# TPCC register map
Vendor: Texas Instruments
Peripheral module from a debugger description file (folder omap36xx).
Registers are 32-bit, read-write, reset values left out (the file's numbers can be read two ways) unless marked. A register's access mark holds for its fields unless they carry their own. Offsets are as the file gives them; lines under a group give offsets from that group; [hi:lo] are bit positions; {n}, {i} and the like mark numbered series; 'fields as' and 'values as' point back to an identical list; <NAME> marks a mode.

## TPCC (part 1 of 2)
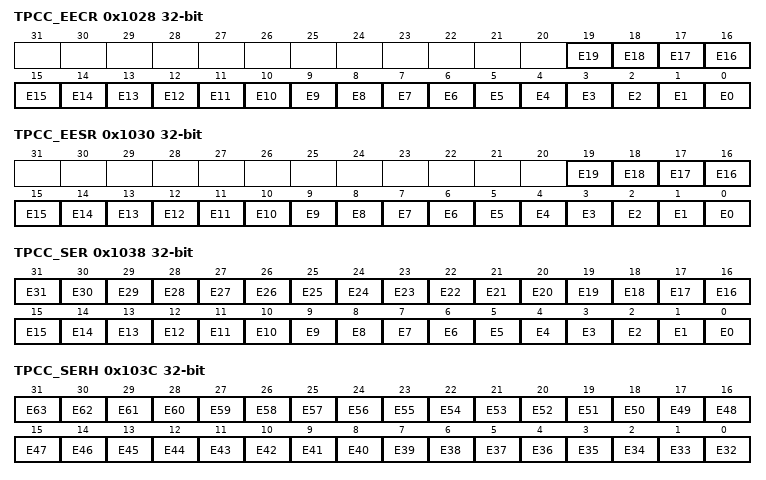
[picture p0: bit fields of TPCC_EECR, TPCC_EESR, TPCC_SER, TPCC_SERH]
0x1028 TPCC_EECR wo — Event Enable Clear Register: CPU write of 1 to the EECR.En bit causes the EER.En bit to be cleared.CPU write of 0 has no effect.
  [n] E{n} (n=0..19) — Event #{n}
0x1030 TPCC_EESR wo — Event Enable Set Register: CPU write of 1 to the EESR.En bit causes the EER.En bit to be set.CPU write of 0 has no effect.
  [n] E{n} (n=0..19) — Event #{n}
0x1038 TPCC_SER ro — Secondary Event Register: The secondary event register is used along with the Event Register (ER) to provide information on the state of an Event. En = 0: Event is not currently in the Event Queue.En = 1: Event is currently stored in Event Queue. Event arbiter will not prioritize additional events.
  [n] E{n} (n=0..31) — Event #{n}
0x103C TPCC_SERH ro — Secondary Event Register (High Part): The secondary event register is used along with the Event Register (ERH) to provide information on the state of an Event. En = 0: Event is not currently in the Event Queue.En = 1: Event is currently stored in Event Queue. Event arbiter will not prioritize additional events.
  [n-32] E{n} (n=32..63) — Event #{n}
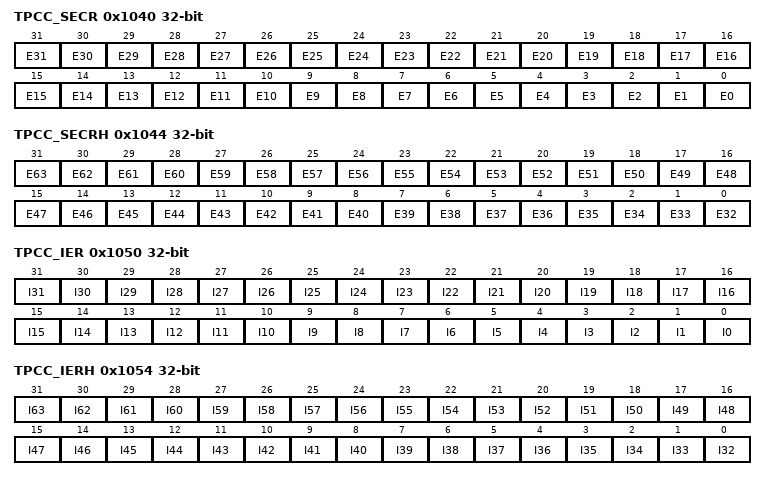
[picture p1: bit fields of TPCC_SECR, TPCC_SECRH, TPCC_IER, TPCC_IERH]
0x1040 TPCC_SECR wo — Secondary Event Clear Register: The secondary event clear register is used to clear the status of the SER registers. CPU write of 1 to the SECR.En bit clears the SER register.CPU write of 0 has no effect.
  [n] E{n} (n=0..31) — Event #{n}
0x1044 TPCC_SECRH wo — Secondary Event Clear Register (High Part): The secondary event clear register is used to clear the status of the SERH registers. CPU write of 1 to the SECRH.En bit clears the SERH register.CPU write of 0 has no effect.
  [n-32] E{n} (n=32..63) — Event #{n}
0x1050 TPCC_IER ro — Int Enable Register: IER.In is not directly writeable. Interrupts can be enabled through writes to IESR and can be disabled through writes to IECR register. IER.In = 0: IPR.In is NOT enabled for interrupts.IER.In = 1: IPR.In IS enabled for interrupts.
  [n] I{n} (n=0..31) — Interrupt associated with TCC #{n}
0x1054 TPCC_IERH ro — Int Enable Register (High Part): IERH.In is not directly writeable. Interrupts canbe enabled through writes to IESRH and can be disabled through writes to IECRH register. IERH.In = 0: IPRH.In is NOT enabled for interrupts.IERH.In = 1: IPRH.In IS enabled for interrupts.
  [n-32] I{n} (n=32..63) — Interrupt associated with TCC #{n}
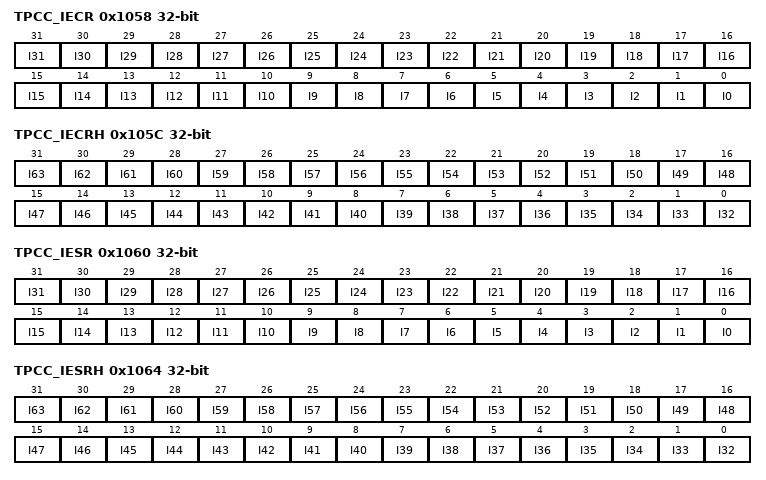
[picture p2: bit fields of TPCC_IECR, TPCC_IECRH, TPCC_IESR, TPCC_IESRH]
0x1058 TPCC_IECR wo — Int Enable Clear Register: CPU write of 1 to the IECR.In bit causes the IER.In bit to be cleared.CPU write of 0 has no effect.
  [n] I{n} (n=0..31) — Interrupt associated with TCC #{n}
0x105C TPCC_IECRH wo — Int Enable Clear Register (High Part): CPU write of 1 to the IECRH.In bit causes the IERH.In bit to be cleared.CPU write of 0 has no effect.
  [n-32] I{n} (n=32..63) — Interrupt associated with TCC #{n}
0x1060 TPCC_IESR wo — Int Enable Set Register: CPU write of 1 to the IESR.In bit causes the IESR.In bit to be set.CPU write of 0 has no effect.
  [n] I{n} (n=0..31) — Interrupt associated with TCC #{n}
0x1064 TPCC_IESRH wo — Int Enable Set Register (High Part): CPU write of 1 to the IESRH.In bit causes the IESRH.In bit to be set.CPU write of 0 has no effect.
  [n-32] I{n} (n=32..63) — Interrupt associated with TCC #{n}
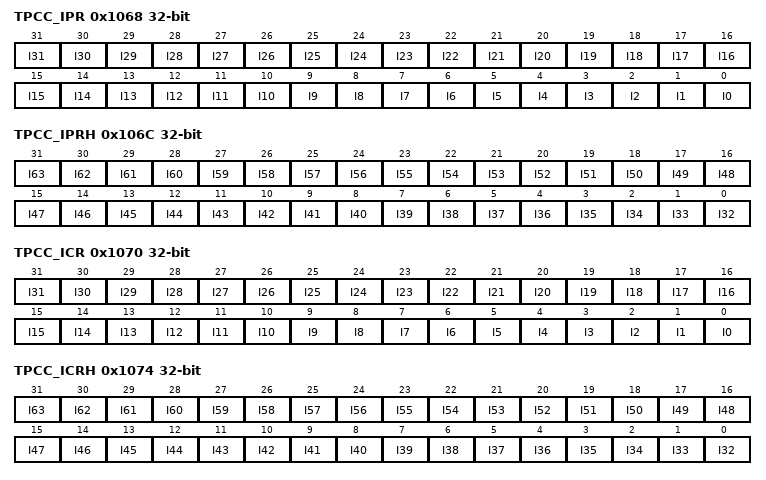
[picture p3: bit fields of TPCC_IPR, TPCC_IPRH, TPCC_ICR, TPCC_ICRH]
0x1068 TPCC_IPR ro — Interrupt Pending Register: IPR.In bit is set when a interrupt completion code with TCC of N is detected.IPR.In bit is cleared through software by writing 1 to ICR.In bit.
  [n] I{n} (n=0..31) — Interrupt associated with TCC #{n}
0x106C TPCC_IPRH ro — Interrupt Pending Register (High Part): IPRH.In bit is set when a interrupt completion code with TCC of N is detected.IPRH.In bit is cleared through software by writing 1 to ICRH.In bit.
  [n-32] I{n} (n=32..63) — Interrupt associated with TCC #{n}
0x1070 TPCC_ICR wo — Interrupt Clear Register: CPU write of 1 to the ICR.In bit causes the IPR.In bit to be cleared.CPU write of 0 has no effect. All IPR.In bits must be cleared before additional interrupts will be asserted by CC.
  [n] I{n} (n=0..31) — Interrupt associated with TCC #{n}
0x1074 TPCC_ICRH wo — Interrupt Clear Register (High Part): CPU write of 1 to the ICRH.In bit causes the IPRH.In bit to be cleared.CPU write of 0 has no effect. All IPRH.In bits must be cleared before additional interrupts will be asserted by CC.
  [n-32] I{n} (n=32..63) — Interrupt associated with TCC #{n}
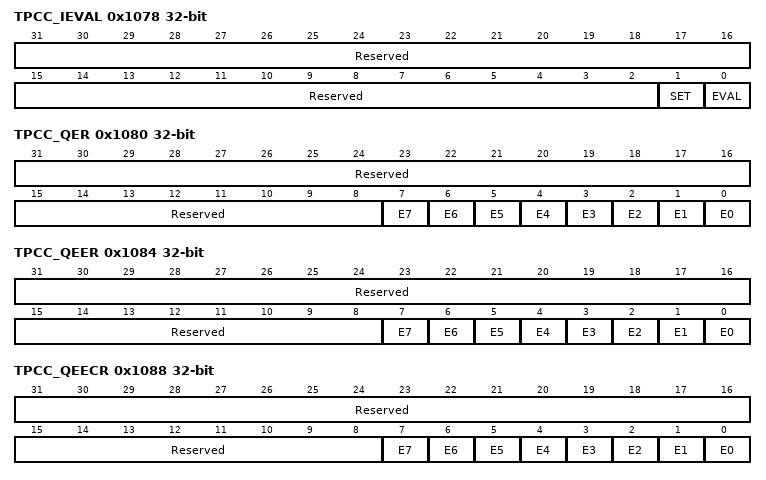
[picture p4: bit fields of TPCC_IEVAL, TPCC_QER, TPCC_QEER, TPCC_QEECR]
0x1078 TPCC_IEVAL wo — Interrupt Eval Register
  [31:2] Reserved — Write 0s for future compatibility.
  [1] SET — Interrupt Set: CPU write of 1 to the SETn bit causes the tpcc_intN output signal to be pulsed egardless of state of interrupts enable (IERn) and status (IPRn).CPU write of 0 has no effect.
  [0] EVAL — Interrupt Evaluate: CPU write of 1 to the EVALn bit causes the tpcc_intN output signal to be pulsed if any enabled interrupts (IERn) are still pending (IPRn).CPU write of 0 has no effect.
0x1080 TPCC_QER ro — QDMA Event Register: If QER.En bit is set, then the corresponding QDMA channel is prioritized vs. other qdma events for submission to the TC. QER.En bit is set when a vbus write byte matches the address defined in the QCHMAPn register. QER.En bit is cleared when the corresponding event is prioritized and serviced. QER.En is also cleared when user writes a 1 to the QSECR.Enbit. If the QER.En bit is already set and a new QDMA event is detected due to user write to QDMA trigger location and QEER register is set, then the corresponding bit in the QDMA Event Missed Register is set.
  [31:8] Reserved — Read returns 0.
  [n] E{n} (n=0..7) — Event #{n}
0x1084 TPCC_QEER ro — QDMA Event Enable Register: Enabled/disabled QDMA address comparator for QDMA Channel N. QEER.En is not directly writeable. QDMA channels can be enabled through writes to QEESR and can be disabled through writes to QEECR register. QEER.En = 1, The corresponding QDMA channel comparator is enabled and Events will be recognized and latched in QER.En.QEER.En = 0, The corresponding QDMA channel comparator is disabled. Events will not be recognized/latched in QER.En.
  [31:8] Reserved — Read returns 0.
  [n] E{n} (n=0..7) — Event #{n}
0x1088 TPCC_QEECR wo — QDMA Event Enable Clear Register: CPU write of 1 to the QEECR.En bit causes the QEER.En bit to be cleared.CPU write of 0 has no effect.
  [31:8] Reserved — Write 0s for future compatibility.
  [n] E{n} (n=0..7) — Event #{n}
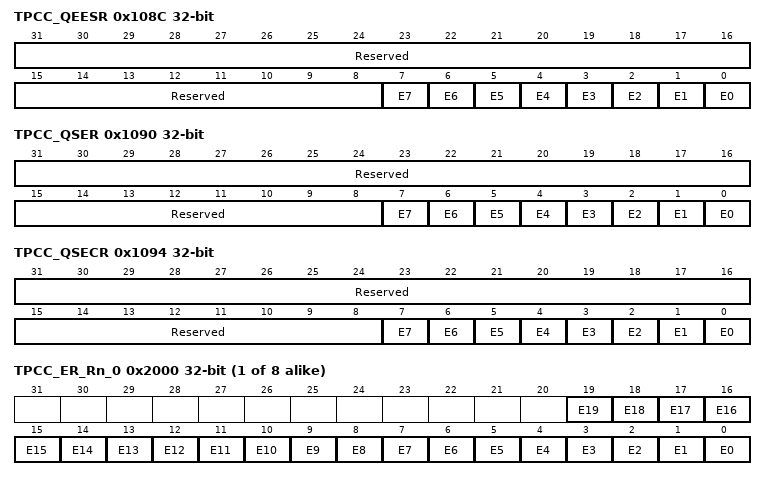
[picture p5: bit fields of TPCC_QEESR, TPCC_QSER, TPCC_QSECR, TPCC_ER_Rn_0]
0x108C TPCC_QEESR wo — QDMA Event Enable Set Register: CPU write of 1 to the QEESR.En bit causes the QEESR.En bit to be set.CPU write of 0 has no effect.
  fields as TPCC_QEECR
0x1090 TPCC_QSER wo — QDMA Secondary Event Register: The QDMA secondary event register is used along with the QDMA Event Register (QER) to provide information on the state of a QDMA Event. En = 0: Event is not currently in the Event Queue.En = 1: Event is currently stored in Event Queue. Event arbiter will not prioritize additional events.
  fields as TPCC_QEECR
0x1094 TPCC_QSECR wo — QDMA Secondary Event Clear Register: The secondary event clear register is used to clear the status of the QSER and QER register (note that this is slightly different than the SER operation, which does not clear the ER.En register). CPU write of 1 to the QSECR.En bit clears the QSER.En and QER.En register fields.CPU write of 0 has no effect.
  fields as TPCC_QEECR
{0x2000+0x200*i} TPCC_ER_Rn_{i} ro (i=0..7) — Event Register: If ER.En bit is set and the EER.En bit is also set, then the corresponding DMA channel is prioritized vs. other pending DMA events for submission to the TC. ER.En bit is set when the input event #n transitions from inactive (low) to active (high), regardless of the state of EER.En bit. ER.En bit is cleared when the corresponding event is prioritized and serviced. If the ER.En bit is already set and a new inactive to active transition is detected on the input event #n input AND the corresponding bit in the EER register is set, then the corresponding bit in the Event Missed Register is set. Event N can be cleared through sw by writing 1 to the ECR pseudo-register.
  [n] E{n} (n=0..19) — Event #{n}
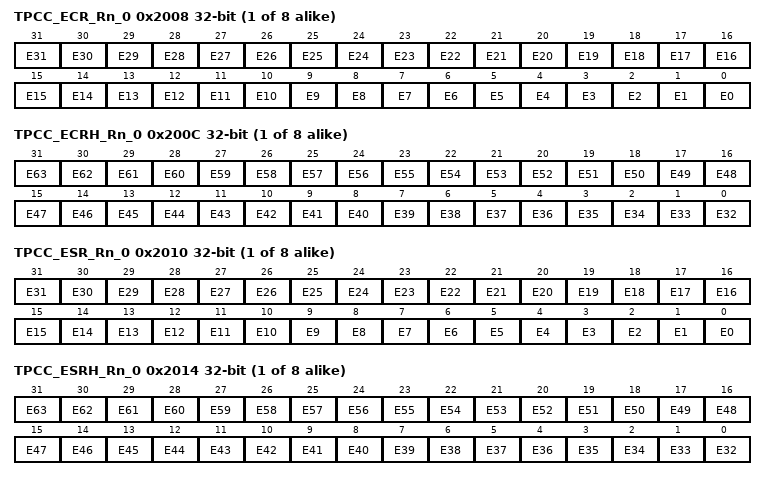
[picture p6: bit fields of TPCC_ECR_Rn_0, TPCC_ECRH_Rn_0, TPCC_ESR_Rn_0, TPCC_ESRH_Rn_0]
{0x2008+0x200*i} TPCC_ECR_Rn_{i} wo (i=0..7) — Event Clear Register: CPU write of 1 to the ECR.En bit causes the ER.En bit to be cleared.CPU write of 0 has no effect.
  [n] E{n} (n=0..31) — Event #{n}
{0x200C+0x200*i} TPCC_ECRH_Rn_{i} wo (i=0..7) — Event Clear Register (High Part): CPU write of 1 to the ECRH.En bit causes the ERH.En bit to be cleared.CPU write of 0 has no effect.
  [n-32] E{n} (n=32..63) — Event #{n}
{0x2010+0x200*i} TPCC_ESR_Rn_{i} wo (i=0..7) — Event Set Register: CPU write of 1 to the ESR.En bit causes the ER.En bit to be set.CPU write of 0 has no effect.
  [n] E{n} (n=0..31) — Event #{n}
{0x2014+0x200*i} TPCC_ESRH_Rn_{i} wo (i=0..7) — Event Set Register (High Part) CPU write of 1 to the ESRH.En bit causes the ERH.En bit to be set.CPU write of 0 has no effect.
  [n-32] E{n} (n=32..63) — Event #{n}
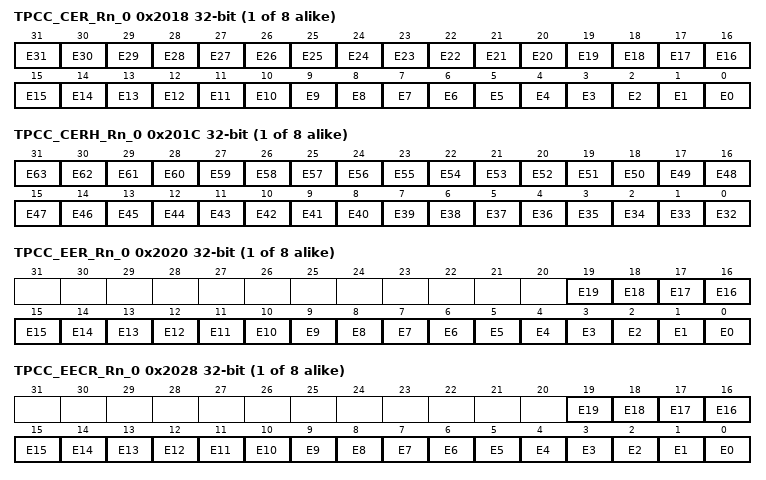
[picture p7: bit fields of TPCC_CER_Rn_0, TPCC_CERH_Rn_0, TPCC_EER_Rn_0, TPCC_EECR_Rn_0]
{0x2018+0x200*i} TPCC_CER_Rn_{i} ro (i=0..7) — Chained Event Register: If CER.En bit is set (regardless of state of EER.En), then the corresponding DMA channel is prioritized vs. other pending DMA events for submission to the TC. CER.En bit is set when a chaining completion code is returned from one of the TPTCs through the completion interface, or is generated internally through Early Completion path. CER.En bit is cleared when the corresponding event is prioritized and serviced. If the CER.En bit is already set and the corresponding chaining completion code is returned from the TC, then the corresponding bit in the Event Missed Register is set. CER.En cannot be set or cleared through software.
  [n] E{n} (n=0..31) — Event #{n}
{0x201C+0x200*i} TPCC_CERH_Rn_{i} ro (i=0..7) — Chained Event Register (High Part): If CERH.En bit is set (regardless of state of EERH.En), then the corresponding DMA channel is prioritized vs. other pending DMA events for submission to the TC. CERH.En bit is set when a chaining completion code is returned from one of the TPTCs through the completion interface, or is generated internally through Early Completion path. CERH.En bit is cleared when the corresponding event is prioritized and serviced. If the CERH.En bit is already set and the corresponding chaining completion code is returned from the TC, then the corresponding bit in the Event Missed Register is set. CERH.En cannot be set or cleared through software.
  [n-32] E{n} (n=32..63) — Event #{n}
{0x2020+0x200*i} TPCC_EER_Rn_{i} ro (i=0..7) — Event Enable Register: Enables DMA transfers for ER.En pending events. ER.En is set based on externally asserted events (through tpcc_eventN_pi). This register has no effect on Chained Event Register (CER) or Event Set Register (ESR). Note that if a bit is set in ER.En while EER.En is disabled, no action is taken. If EER.En is enabled at a later point (and ER.En has not been cleared through SW) then the event will be recognized as a valid TR Sync EER.En is not directly writeable. Events can be enabled through writes to EESR and can be disabled through writes to EECR register. EER.En = 0: ER.En is not enabled to trigger DMA transfers.EER.En = 1: ER.En is enabled to trigger DMA transfers.
  [n] E{n} (n=0..19) — Event #{n}
{0x2028+0x200*i} TPCC_EECR_Rn_{i} wo (i=0..7) — Event Enable Clear Register: CPU write of 1 to the EECR.En bit causes the EER.En bit to be cleared.CPU write of 0 has no effect.
  [n] E{n} (n=0..19) — Event #{n}
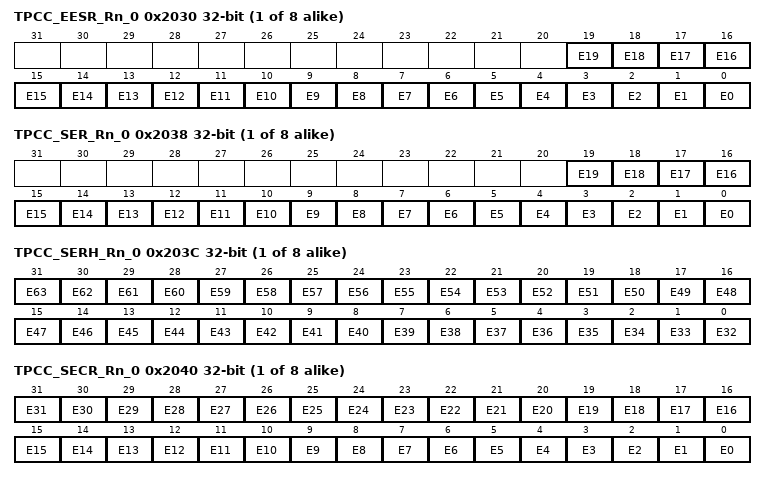
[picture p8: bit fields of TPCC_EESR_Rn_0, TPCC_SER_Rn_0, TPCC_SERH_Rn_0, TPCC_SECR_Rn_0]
{0x2030+0x200*i} TPCC_EESR_Rn_{i} wo (i=0..7) — Event Enable Set Register: CPU write of 1 to the EESR.En bit causes the EER.En bit to be set.CPU write of 0 has no effect.
  [n] E{n} (n=0..19) — Event #{n}
{0x2038+0x200*i} TPCC_SER_Rn_{i} ro (i=0..7) — Secondary Event Register: The secondary event register is used along with the Event Register (ER) to provide information on the state of an Event. En = 0: Event is not currently in the Event Queue.En = 1: Event is currently stored in Event Queue. Event arbiter will not prioritize additional events.
  [n] E{n} (n=0..19) — Event #{n}
{0x203C+0x200*i} TPCC_SERH_Rn_{i} ro (i=0..7) — Secondary Event Register (High Part): The secondary event register is used along with the Event Register (ERH) to provide information on the state of an Event. En = 0: Event is not currently in the Event Queue.En = 1: Event is currently stored in Event Queue. Event arbiter will not prioritize additional events.
  [n-32] E{n} (n=32..63) — Event #{n}
{0x2040+0x200*i} TPCC_SECR_Rn_{i} wo (i=0..7) — Secondary Event Clear Register: The secondary event clear register is used to clear the status of the SER registers. CPU write of 1 to the SECR.En bit clears the SER register.CPU write of 0 has no effect.
  [n] E{n} (n=0..31) — Event #{n}
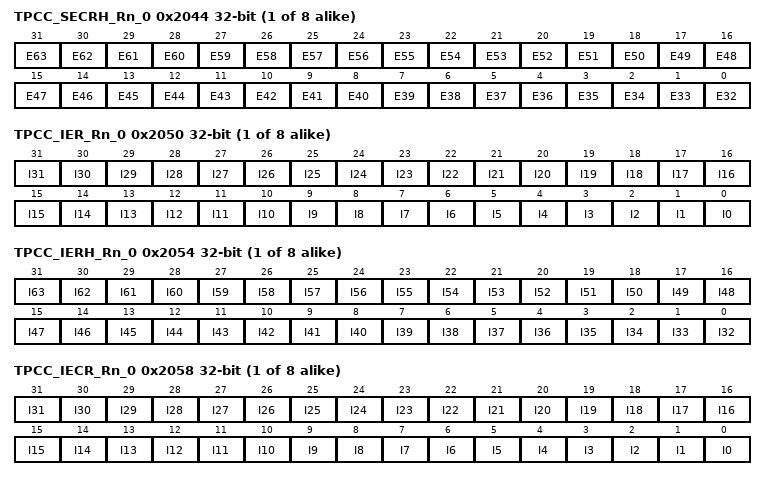
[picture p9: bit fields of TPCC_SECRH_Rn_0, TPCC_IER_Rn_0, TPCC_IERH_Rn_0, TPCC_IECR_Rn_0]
{0x2044+0x200*i} TPCC_SECRH_Rn_{i} wo (i=0..7) — Secondary Event Clear Register (High Part): The secondary event clear register is used to clear the status of the SERH registers. CPU write of 1 to the SECRH.En bit clears the SERH register.CPU write of 0 has no effect.
  [n-32] E{n} (n=32..63) — Event #{n}
{0x2050+0x200*i} TPCC_IER_Rn_{i} ro (i=0..7) — Int Enable Register: IER.In is not directly writeable. Interrupts can be enabled through writes to IESR and can be disabled through writes to IECR register. IER.In = 0: IPR.In is NOT enabled for interrupts.IER.In = 1: IPR.In IS enabled for interrupts.
  [n] I{n} (n=0..31) — Interrupt associated with TCC #{n}
{0x2054+0x200*i} TPCC_IERH_Rn_{i} ro (i=0..7) — Int Enable Register (High Part): IERH.In is not directly writeable. Interrupts can be enabled through writes to IESRH and can be disabled through writes to IECRH register. IERH.In = 0: IPRH.In is NOT enabled for interrupts.IERH.In = 1: IPRH.In IS enabled for interrupts.
  [n-32] I{n} (n=32..63) — Interrupt associated with TCC #{n}
{0x2058+0x200*i} TPCC_IECR_Rn_{i} wo (i=0..7) — Int Enable Clear Register: CPU write of 1 to the IECR.In bit causes the IER.In bit to be cleared.CPU write of 0 has no effect.
  [n] I{n} (n=0..31) — Interrupt associated with TCC #{n}
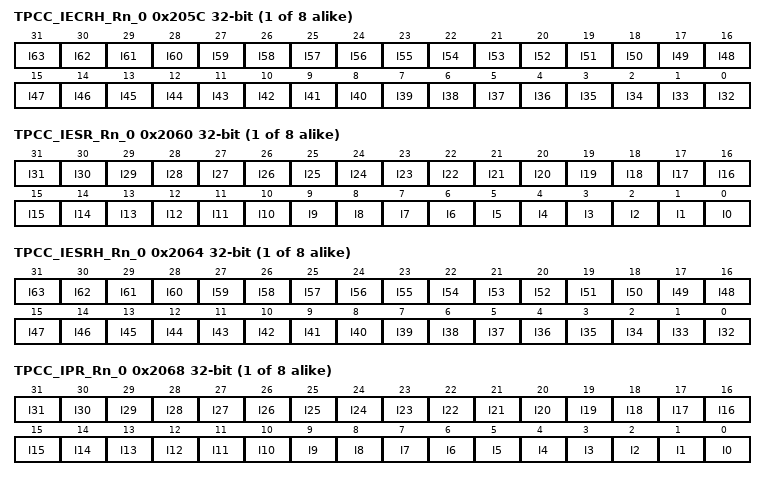
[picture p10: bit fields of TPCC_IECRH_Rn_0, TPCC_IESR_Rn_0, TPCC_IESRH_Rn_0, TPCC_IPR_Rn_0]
{0x205C+0x200*i} TPCC_IECRH_Rn_{i} wo (i=0..7) — Int Enable Clear Register (High Part): CPU write of 1 to the IECRH.In bit causes the IERH.In bit to be cleared.CPU write of 0 has no effect.
  [n-32] I{n} (n=32..63) — Interrupt associated with TCC #{n}
{0x2060+0x200*i} TPCC_IESR_Rn_{i} wo (i=0..7) — Int Enable Set Register: CPU write of 1 to the IESR.In bit causes the IESR.In bit to be set.CPU write of 0 has no effect.
  [n] I{n} (n=0..31) — Interrupt associated with TCC #{n}
{0x2064+0x200*i} TPCC_IESRH_Rn_{i} wo (i=0..7) — Int Enable Set Register (High Part): CPU write of 1 to the IESRH.In bit causes the IESRH.In bit to be set.CPU write of 0 has no effect.
  [n-32] I{n} (n=32..63) — Interrupt associated with TCC #{n}
{0x2068+0x200*i} TPCC_IPR_Rn_{i} ro (i=0..7) — Interrupt Pending Register: IPR.In bit is set when a interrupt completion code with TCC of N is detected.IPR.In bit is cleared through software by writing 1 to ICR.In bit.
  [n] I{n} (n=0..31) — Interrupt associated with TCC #{n}
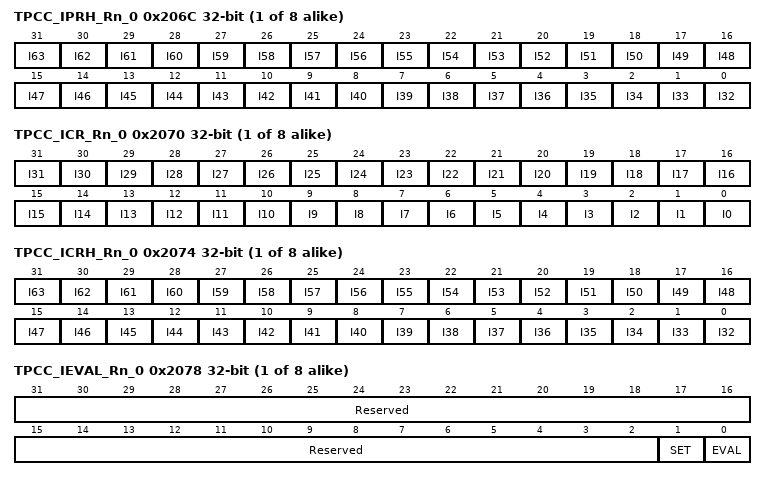
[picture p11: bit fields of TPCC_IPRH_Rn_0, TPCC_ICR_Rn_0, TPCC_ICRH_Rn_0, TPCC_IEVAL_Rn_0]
{0x206C+0x200*i} TPCC_IPRH_Rn_{i} ro (i=0..7) — Interrupt Pending Register (High Part): IPRH.In bit is set when a interrupt completion code with TCC of N is detected.IPRH.In bit is cleared through software by writing 1 to ICRH.In bit.
  [n-32] I{n} (n=32..63) — Interrupt associated with TCC #{n}
{0x2070+0x200*i} TPCC_ICR_Rn_{i} wo (i=0..7) — Interrupt Clear Register: CPU write of 1 to the ICR.In bit causes the IPR.In bit to be cleared.CPU write of 0 has no effect. All IPR.In bits must be cleared before additional interrupts will be asserted by CC.
  [n] I{n} (n=0..31) — Interrupt associated with TCC #{n}
{0x2074+0x200*i} TPCC_ICRH_Rn_{i} wo (i=0..7) — Interrupt Clear Register (High Part): CPU write of 1 to the ICRH.In bit causes the IPRH.In bit to be cleared.CPU write of 0 has no effect. All IPRH.In bits must be cleared before additional interrupts will be asserted by CC.
  [n-32] I{n} (n=32..63) — Interrupt associated with TCC #{n}
{0x2078+0x200*i} TPCC_IEVAL_Rn_{i} wo (i=0..7) — Interrupt Eval Register
  fields as TPCC_IEVAL
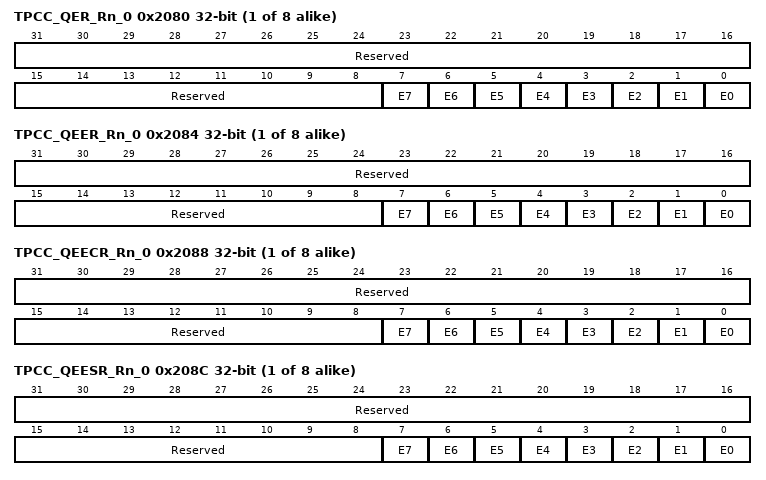
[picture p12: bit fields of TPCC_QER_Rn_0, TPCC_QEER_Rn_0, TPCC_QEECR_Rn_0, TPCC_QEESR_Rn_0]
{0x2080+0x200*i} TPCC_QER_Rn_{i} ro (i=0..7) — QDMA Event Register: If QER.En bit is set, then the corresponding QDMA channel is prioritized vs. other qdma events for submission to the TC. QER.En bit is set when a vbus write byte matches the address defined in the QCHMAPn register. QER.En bit is cleared when the corresponding event is prioritized and serviced. QER.En is also cleared when user writes a 1 to the QSECR.Enbit. If the QER.En bit is already set and a new QDMA event is detected due to user write to QDMA trigger location and QEER register is set, then the corresponding bit in the QDMA Event Missed Register is set.
  [31:8] Reserved — Read returns 0.
  [n] E{n} (n=0..7) — Event #{n}
{0x2084+0x200*i} TPCC_QEER_Rn_{i} ro (i=0..7) — QDMA Event Enable Register: Enabled/disabled QDMA address comparator for QDMA Channel N. QEER.En is not directly writeable. QDMA channels can be enabled through writes to QEESR and can be disabled through writes to QEECR register. QEER.En = 1, The corresponding QDMA channel comparator is enabled and Events will be recognized and latched in QER.En.QEER.En = 0, The corresponding QDMA channel comparator is disabled. Events will not be recognized/latched in QER.En.
  [31:8] Reserved — Read returns 0.
  [n] E{n} (n=0..7) — Event #{n}
{0x2088+0x200*i} TPCC_QEECR_Rn_{i} wo (i=0..7) — QDMA Event Enable Clear Register: CPU write of 1 to the QEECR.En bit causes the QEER.En bit to be cleared.CPU write of 0 has no effect.
  fields as TPCC_QEECR
{0x208C+0x200*i} TPCC_QEESR_Rn_{i} wo (i=0..7) — QDMA Event Enable Set Register: CPU write of 1 to the QEESR.En bit causes the QEESR.En bit to be set.CPU write of 0 has no effect.
  fields as TPCC_QEECR
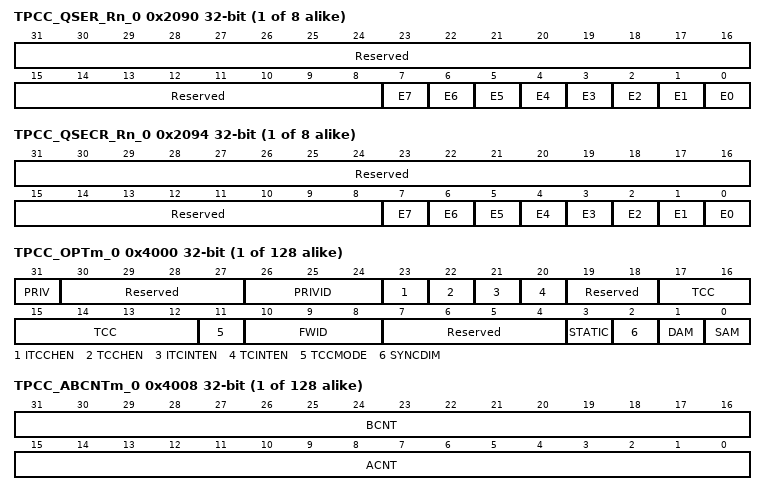
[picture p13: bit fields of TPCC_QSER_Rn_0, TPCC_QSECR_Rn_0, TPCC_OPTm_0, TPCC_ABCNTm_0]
{0x2090+0x200*i} TPCC_QSER_Rn_{i} ro (i=0..7) — QDMA Secondary Event Register: The QDMA secondary event register is used along with the QDMA Event Register (QER) to provide information on the state of a QDMA Event. En = 0: Event is not currently in the Event Queue.En = 1: Event is currently stored in Event Queue. Event arbiter will not prioritize additional events.
  [31:8] Reserved — Read returns 0.
  [n] E{n} (n=0..7) — Event #{n}
{0x2094+0x200*i} TPCC_QSECR_Rn_{i} wo (i=0..7) — QDMA Secondary Event Clear Register: The secondary event clear register is used to clear the status of the QSER and QER register (note that this is slightly different than the SER operation, which does not clear the ER.En register). CPU write of 1 to the QSECR.En bit clears the QSER.En and QER.En register fields.CPU write of 0 has no effect.
  fields as TPCC_QEECR
{0x4000+0x20*i} TPCC_OPTm_{i} access per field (i=0..127) — Options Parameter
  [31] PRIV ro — Privilege level: Privilege level (supervisor vs. user) for the host/cpu/dma that programmed this PaRAM Entry. Value is set with the vbus priv value when any part of the PaRAM Entry is written. Not writeable through vbus wdata bus. Is readable through VBus rdata bus. PRIV = 0: User level privilegePRIV = 1: Supervisor level privilege
  [30:27] Reserved rw — Write 0s for future compatibility.Read returns 0.
  [26:24] PRIVID ro — Privilege ID: Privilege ID for the external host/cpu/dma that programmed this PaRAM Entry. This value is set with the vbus privid value when any part of the PaRAM Entry is written. Not writeable through vbus wdata bus. Is readable through VBus rdata bus.
  [23] ITCCHEN rw — Intermediate transfer completion chaining enable: 0: Intermediate transfer complete chaining is disabled.1: Intermediate transfer complete chaining is enabled.
  [22] TCCHEN rw — Transfer complete chaining enable: 0: Transfer complete chaining is disabled.1: Transfer complete chaining is enabled.
  [21] ITCINTEN rw — Intermediate transfer completion interrupt enable: 0: Intermediate transfer complete interrupt is disabled.1: Intermediate transfer complete interrupt is enabled (corresponding IER[TCC] bit must be set to 1 to generate interrupt)
  [20] TCINTEN rw — Transfer complete interrupt enable: 0: Transfer complete interrupt is disabled.1: Transfer complete interrupt is enabled (corresponding IER[TCC] bit must be set to 1 to generate interrupt)
  [19:18] Reserved rw — Write 0s for future compatibility.Read returns 0.
  [17:12] TCC rw — Transfer Complete Code: The 6-bit code is used to set the relevant bit in CER (bit CER[TCC]) for chaining or in IER (bit IER[TCC]) for interrupts.
  [11] TCCMODE rw — Transfer complete code mode: Indicates the point at which a transfer is considered completed. Applies to both chaining and interrupt. 0: Normal Completion, A transfer is considered completed after the transfer parameters are returned to the CC from the TC (which was returned from the peripheral).1: Early Completion, A transfer is considered completed after the CC submits a TR to the TC. CC generates completion code internally .
  [10:8] FWID rw — FIFO width: Applies if either SAM or DAM is set to FIFO mode. Pass-thru to TC.
    0=FIFO width is 8-bit; 1=FIFO width is 16-bit; 2=FIFO width is 32-bit; 3=FIFO width is 64-bit; 4=FIFO width is 128-bit; 5=FIFO width is 256-bit
  [7:4] Reserved rw — Write 0s for future compatibility.Read returns 0.
  [3] STATIC rw — Static Entry: 0: Entry is updated as normal1: Entry is static, Count and Address updates are not updated after TRP is submitted. Linking is not performed.
  [2] SYNCDIM rw — Transfer Synchronization Dimension: 0: A-Sync, Each event triggers the transfer of ACNT elements.1: AB-Sync, Each event triggers the transfer of BCNT arrays of ACNT elements
  [1] DAM rw — Destination Address Mode: Destination Address Mode within an array. Pass-thru to TC. 0: INCR, Dst addressing within an array increments. Dst is not a FIFO.1: FIFO, Dst addressing within an array wraps around upon reaching FIFO width.
  [0] SAM rw — Source Address Mode: Source Address Mode within an array. Pass-thru to TC. 0: INCR, Src addressing within an array increments. Source is not a FIFO.1: FIFO, Src addressing within an array wraps around upon reaching FIFO width.
{0x4004+0x20*i} TPCC_SRCm_{i} (i=0..127) — Source Address
  [31:0] SRC — Source Address: The 32-bit source address parameters specify the starting byte address of the source. If SAM is set to FIFO mode then the user should program the Source address to be aligned to the value specified by the OPT.FWID field. No errors are recognized here but TC will assert error if this is not true.
{0x4008+0x20*i} TPCC_ABCNTm_{i} (i=0..127) — A and B byte count
  [31:16] BCNT — BCNT : Count for 2nd Dimension: BCNT is a 16-bit unsigned value that specifies the number of arrays of length ACNT. For normal operation, valid values for BCNT can be anywhere between 1 and 65535. Therefore, the maximumNumber of arrays in a frame is 65535 (64K-1 arrays). BCNT=1 means 1 array in the frame, and BCNT=0 means 0 arrays in the frame. In normal mode, a BCNT of 0 is considered as either a Null or Dummy transfer. A Dummy or Null transfer will generate a Completion code depending on the settings of the completion bit fields of the OPT field. If the OPTi.WIMODE bit is set, then the programmed BCNT value will be incremented by 1 before submission to TC. I.e., 0 means 1, 1 means 2, 2 means 3, ..., 0xFFFE means 0xFFFF. A value of 0xFFFF is an illegal value that will be treated as a Null TR.
  [15:0] ACNT — ACNT : number of bytes in 1st dimension: ACNT represents the number of bytes within the first dimension of a transfer. ACNT is a 16-bit unsigned value with valid values between 0 and 65535. Therefore, the maximum number of bytes in an array is 65535 bytes (64K-1 bytes). ACNT must be greater than or equal to 1 for a TR to be submitted to TC. An ACNT of 0 is considered as either a null or dummy transfer. A Dummy or Null transfer will generate a Completion code depending on the settings of the completion bit fields of the OPT field. If the OPTi.WIMODE bit is set then the ACNT field represents a word count. The CC must internally multiply by 4 to translate the word count to a byte count prior to submission to the TC. The 2 MSBs of the 16-bit ACNT are Reserved and should always be written as b00 by the user. If user writes a value other than 0, it will still be treated as 0 since the multiply-by-4 operation (to translate between a word count and a byte count) will drop the 2 msbits. For dummy and null transfer definition, the ACNT definition will disregard the 2 msbits. I.e., a programmed ACNT value of 0x8000 in WI-mode will be treated as 0 byte transfer, resulting in null or dummy operation dependent on the state of BCNT and CCNT.
{0x400C+0x20*i} TPCC_DSTm_{i} (i=0..127) — Destination Address
  [31:0] DST — Destination Address: The 32-bit destination address parameters specify the starting byte address of the destination. If DAM is set to FIFO mode then the user should program the Destination address to be aligned to the value specified by the OPTi.FWID field. No errors are recognized here but TC will assert error if this is not true.
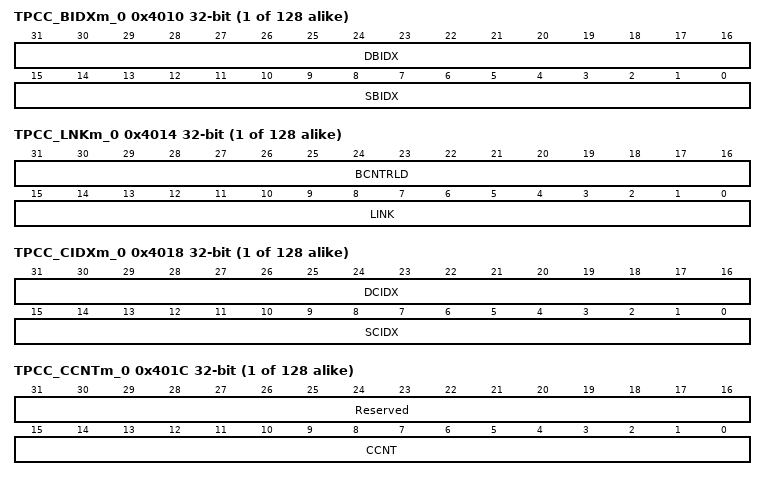
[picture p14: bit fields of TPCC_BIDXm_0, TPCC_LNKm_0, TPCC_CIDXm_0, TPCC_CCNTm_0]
{0x4010+0x20*i} TPCC_BIDXm_{i} (i=0..127)
  [31:16] DBIDX — Destination 2nd Dimension Index: DBIDX is a 16-bit signed value (2s complement) used for destination address modification in between each array in the 2nd dimension. It is a signed value between -32768 and 32767. It provides a byte address offset from the beginning of the destination array to the beginning of the next destination array within the current frame. It applies to both A-Sync and AB-Sync transfers.
  [15:0] SBIDX — Source 2nd Dimension Index: SBIDX is a 16-bit signed value (2s complement) used for source address modification in between each array in the 2nd dimension. It is a signed value between - 32768 and 32767. It provides a byteaddress offset from the beginning of the source array to the beginning of the next source array. It applies to both A-sync and AB-sync transfers.
{0x4014+0x20*i} TPCC_LNKm_{i} (i=0..127) — Link and Reload parameters
  [31:16] BCNTRLD — BCNT Reload: BCNTRLD is a 16-bit unsigned value used to reload the BCNT field once the last array in the 2nd dimension is transferred. This field is only used for A-Synced transfers. In this case, the CC decrements the BCNT value by one on each TR submission. When BCNT (conceptually) reaches zero, then the CC decrements CCNT and uses the BCNTRLD value to reinitialize the BCNT value. For AB-synchronized transfers, the CC submits the BCNT in the TR and therefore the TC is responsible to keep track of BCNT, not CC-thus BCNTRLD is a dont care field.
  [15:0] LINK — Link Address: The CC provides a mechanism to reload the current PaRAM Entry upon its natural termination (i.e., after count fields are decremented to 0) with a new PaRAM Entry. This is called linking. The 16-bit parameter LINK specifies the byte address offset in the PaRAM from which the CC loads/reloads the next PaRAM entry in the link. The CC should disregard the value in the upper 2 bits of the LINK field as well as the lower 5-bits of the LINK field. The upper two bits are ignored such that the user can program either the literal byte address of the LINK parameter or the PaRAM base-relative address of the link field. Therefore, if the user uses the literal address with a range from 0x4000 to 0x7FFF, it will be treated as a PaRAM-base-relative valueof 0x0000 to 0x3FFF. The lower-5 bits are ignored and treated as b00000, thereby guaranteeing that all Link pointers point to a 32-byte aligned PaRAM entry. In the latter case (5-lsbs), behavior is undefined for the user (i.e., dont have to test it). In the former case (2 msbs), user should be able to take advantage of this feature (i.e., do have to test it). If a Link Update is requested to a PaRAM address that is beyond the actual range of implemented PaRAM, then the Link will be treated as a Null Linkand all 0s plus 0xFFFF will be written to the current entry location. A LINK value of 0xFFFF is referred to as a NULL link which should cause the CC to write 0x0 to all entries of the current PaRAM Entry except for the LINK field which is set to 0xFFFF. The Priv/Privid state is overwritten to 0x0 when linking. MSBs and LSBS should not be masked when comparing against the 0xFFFF value. I.e., a value of 0x3FFE is a non-NULL PaRAM link field.
{0x4018+0x20*i} TPCC_CIDXm_{i} (i=0..127)
  [31:16] DCIDX — Destination Frame Index: DCIDX is a 16-bit signed value (2s complement) used for destination address modification for the 3rd dimension. It is a signed value between -32768 and 32767. It provides a byte address offset from the beginning of the current array (pointed to by DST address) to the beginning of the first destination array in the next frame. It applies to both A-sync and AB-sync transfers. Note that when DCIDX is applied, the current array in anA-sync transfer is the last array in the frame, while the current array in a ABsync transfer is the first array in the frame.
  [15:0] SCIDX — Source Frame Index: SCIDX is a 16-bit signed value (2s complement) used for source address modification for the 3rd dimension. It is a signed value between -32768 and 32767. It provides a byte address offset from thebeginning of the current array (pointed to by SRC address) to the beginning of the first source array in the next frame. It applies to both A-sync and AB-sync transfers. Note that when SCIDX is applied, the current arraya in an A-sync transfer is the last array in the frame, while the current array in a AB-sync transfer is the first array in the frame.
{0x401C+0x20*i} TPCC_CCNTm_{i} (i=0..127) — C byte count
  [31:16] Reserved — Write 0s for future compatibility.Read returns 0.
  [15:0] CCNT — CCNT Count for 3rd Dimension: CCNT is a 16-bit unsigned value that specifies the number of frames in a block. Valid values for CCNT can be anywhere between 1 and 65535. Therefore, the maximum number of frames in a block is 65535 (64K-1 frames). CCNT of 1 means 1 frame in the block, and CCNT of 0 means 0 frames in the block. A CCNT value of 0 is considered as either a null or dummy transfer. A Dummy or Null transfer will generate a Completion code depending on the settings of the completion bit fields of the OPTi field. WIMODE has no affect on CCNT operation.
